# nrf54lv10a_application register map
Vendor: Nordic Semiconductor; Series: nrf54l; File version: 1
CPU: CM33 r0p4, little endian, MPU, FPU, 3 interrupt priority bits, 270 interrupts, 4 SAU regions
Registers are 32-bit, read-write, reset 0x0 unless marked. A register's access mark holds for its fields unless they carry their own. Offsets are from the block's base; [hi:lo] are bit positions; lines under a group give offsets from that group; {n}, {i} and the like mark numbered series; 'fields as' and 'values as' point back to an identical list.

## GLOBAL_RRAMC_S — RRAM controller GLITCH detector
Base 0x5004E000; alternate view of GLOBAL_GLITCHDET_S
0x00 TASKS_WAKEUP wo — Wakeup the RRAM from low power mode
  [0] TASKS_WAKEUP
    1=Trigger task
0x04 TASKS_CLRWRITEBUF wo — Clear internal write-buffer
  [0] TASKS_CLRWRITEBUF
    1=Trigger task
0x08 TASKS_COMMITWRITEBUF wo — Commits the data stored in internal write-buffer to RRAM
  [0] TASKS_COMMITWRITEBUF
    1=Trigger task
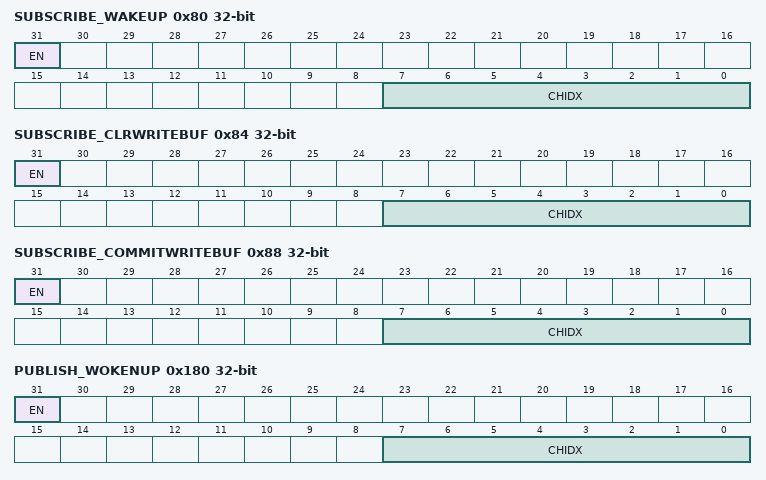
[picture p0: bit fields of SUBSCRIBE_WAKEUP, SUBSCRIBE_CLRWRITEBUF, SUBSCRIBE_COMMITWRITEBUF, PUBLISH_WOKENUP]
0x80 SUBSCRIBE_WAKEUP — Subscribe configuration for task WAKEUP
  [31] EN
    0=Disabled (Disable subscription); 1=Enabled (Enable subscription)
  [7:0] CHIDX — DPPI channel that task WAKEUP will subscribe to
0x84 SUBSCRIBE_CLRWRITEBUF — Subscribe configuration for task CLRWRITEBUF
  [31] EN
    values as SUBSCRIBE_WAKEUP.EN
  [7:0] CHIDX — DPPI channel that task CLRWRITEBUF will subscribe to
0x88 SUBSCRIBE_COMMITWRITEBUF — Subscribe configuration for task COMMITWRITEBUF
  [31] EN
    values as SUBSCRIBE_WAKEUP.EN
  [7:0] CHIDX — DPPI channel that task COMMITWRITEBUF will subscribe to
0x100 EVENTS_WOKENUP — RRAMC is woken up from low power mode
  [0] EVENTS_WOKENUP
    0=NotGenerated (Event not generated); 1=Generated (Event generated)
0x104 EVENTS_READY — RRAMC is ready
  [0] EVENTS_READY
    values as EVENTS_WOKENUP.EVENTS_WOKENUP
0x108 EVENTS_READYNEXT — Ready to accept a new write operation
  [0] EVENTS_READYNEXT
    values as EVENTS_WOKENUP.EVENTS_WOKENUP
0x10C EVENTS_ACCESSERROR — RRAM access error
  [0] EVENTS_ACCESSERROR
    values as EVENTS_WOKENUP.EVENTS_WOKENUP
0x180 PUBLISH_WOKENUP — Publish configuration for event WOKENUP
  [31] EN
    0=Disabled (Disable publishing); 1=Enabled (Enable publishing)
  [7:0] CHIDX — DPPI channel that event WOKENUP will publish to
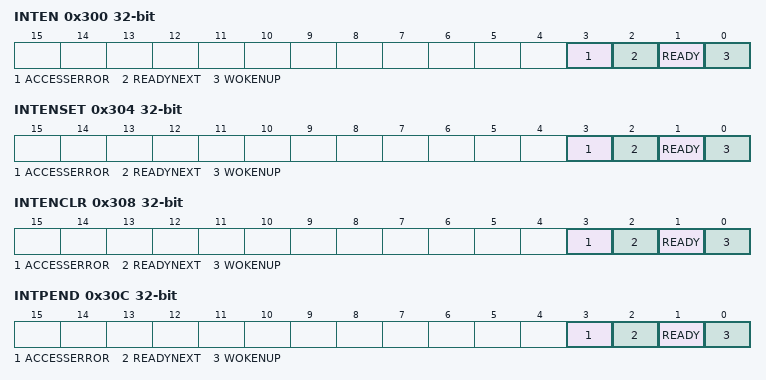
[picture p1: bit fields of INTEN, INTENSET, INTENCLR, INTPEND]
0x300 INTEN — Enable or disable interrupt
  [all] fields
    0=Disabled; 1=Enabled
  [3] ACCESSERROR — Enable or disable interrupt for event ACCESSERROR
  [2] READYNEXT — Enable or disable interrupt for event READYNEXT
  [1] READY — Enable or disable interrupt for event READY
  [0] WOKENUP — Enable or disable interrupt for event WOKENUP
0x304 INTENSET — Enable interrupt
  [all] fields
    on read: 0=Disabled (Read: Disabled); 1=Enabled (Read: Enabled) | on write: 1=Set (Enable)
  [3] ACCESSERROR write-1-sets — Write '1' to enable interrupt for event ACCESSERROR
  [2] READYNEXT write-1-sets — Write '1' to enable interrupt for event READYNEXT
  [1] READY write-1-sets — Write '1' to enable interrupt for event READY
  [0] WOKENUP write-1-sets — Write '1' to enable interrupt for event WOKENUP
0x308 INTENCLR — Disable interrupt
  [all] fields
    on read: 0=Disabled (Read: Disabled); 1=Enabled (Read: Enabled) | on write: 1=Clear (Disable)
  [3] ACCESSERROR write-1-clears — Write '1' to disable interrupt for event ACCESSERROR
  [2] READYNEXT write-1-clears — Write '1' to disable interrupt for event READYNEXT
  [1] READY write-1-clears — Write '1' to disable interrupt for event READY
  [0] WOKENUP write-1-clears — Write '1' to disable interrupt for event WOKENUP
0x30C INTPEND ro — Pending interrupts
  [all] fields
    on read: 0=NotPending (Read: Not pending); 1=Pending (Read: Pending)
  [3] ACCESSERROR — Read pending status of interrupt for event ACCESSERROR
  [2] READYNEXT — Read pending status of interrupt for event READYNEXT
  [1] READY — Read pending status of interrupt for event READY
  [0] WOKENUP — Read pending status of interrupt for event WOKENUP
0x400 READY ro — RRAMC ready status
  [0] READY — RRAMC is ready or busy
    0=Busy (RRAMC is busy); 1=Ready (The current RRAMC operation is completed and RRAMC is ready)
0x404 READYNEXT ro — Ready next flag
  [0] READYNEXT — RRAMC can accept a new write operation
    0=Busy (RRAMC cannot accept any write operation now); 1=Ready (RRAMC is ready to accept a new write operation)
0x408 ACCESSERRORADDR ro reset 0xFFFFFF — Address of the first access error
  [31:0] ADDRESS — Access error address
0x410 BUFSTATUS group — Unspecified
  0x08 WRITEBUFEMPTY ro — Internal write-buffer is empty
    [0] EMPTY
      0=NotEmpty (The internal write-buffer has data that needs committing); 1=Empty (The internal write-buffer is empty and has no content that needs to be committed)
0x420 ECC group — Unspecified
  0x00 ERRORADDR ro reset 0xFFFFFF — Address of the first ECC error that could not be corrected
    [31:0] ADDRESS — ECC error address
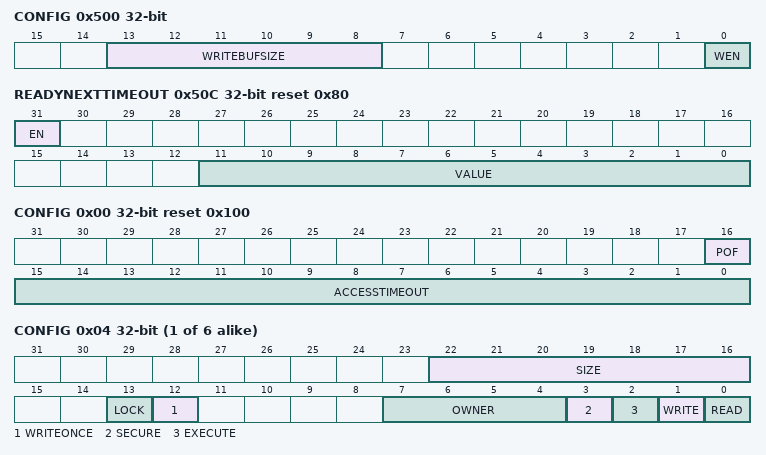
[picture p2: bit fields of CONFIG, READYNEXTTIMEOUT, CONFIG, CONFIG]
0x500 CONFIG — Configuration register
  [13:8] WRITEBUFSIZE — Write-buffer size in number of data units
    0=Unbuffered (Disable buffering)
  [0] WEN — Write enable
    0=Disabled (Write is disabled); 1=Enabled (Write is enabled)
0x50C READYNEXTTIMEOUT reset 0x80 — Configuration for ready next timeout counter, in units of AXI clock frequency
  [31] EN — Enable ready next timeout
    0=Disable ready next timeout; 1=Enable ready next timeout
  [11:0] VALUE — Preload value for waiting for a next write
0x510 POWER group — Unspecified
  0x00 CONFIG reset 0x100 — Power configuration
    [16] POF — Power on failure warning handling configuration
      0=Wait until the current RRAM write finishes; 1=Abort the current RRAM write
    [15:0] ACCESSTIMEOUT — Access timeout, in 31.25 ns units, used for going into standby power mode or remain active on wake up
  0x04 STANDBYCONFIG — Standby mode configuration
    [1:0] MODE — RRAM standby mode
      0=Normal (The RRAM automatically goes into idle mode while the RRAM is not being accessed); 1=NAP (The RRAM goes into NAP mode when the access timeout counter is expired); 2=PowerDown (The RRAM goes into power down mode when the access timeout counter is expired); 3=Standby (The RRAM remains active while the RRAM is not being accessed.)
  0x08 LOWPOWERCONFIG — Low power mode configuration
    [1:0] MODE — RRAM low power mode
      0=PowerDown (The RRAM goes into power down mode); 1=Standby (The RRAM automatically goes into standby mode while the RRAM is not being accessed); 2=NAP (The RRAM goes into NAP mode); 3=PowerOff (The RRAM is powered Off)
0x540 ERASE group — Unspecified
  0x00 ERASEALL — Erase RRAM, including UICR All information in SICR, including keys, are also erased
    [0] ERASE — Erase RRAM
      0=NoOperation; 1=Erase (Start erase of chip)
{0x550+8i} REGION[{i}] (i=0..5) group — RRAMC can apply access privileges to regions of the RRAM. Some regions are dedicated for system use and are not available for configuration - refer to the instantiation table for details.
  0x00 ADDRESS — Description cluster: Region address
    [31:0] STARTADDR — Start address of the region [n]
  0x04 CONFIG — Description cluster: Region configuration
    [22:16] SIZE — Size in KBytes of region [n]
    [13] LOCK write-1-sets — Enable lock
      0=Disabled (Lock disabled for region [n]); 1=Enabled (Lock enabled for region [n])
    [12] WRITEONCE
      0=Disabled (Write-once disabled); 1=Enabled (Write-once enabled)
    [7:4] OWNER — Owner ID
      0=NotEnforced (Owner ID protection is not enforced)
    [3] SECURE — Secure access
      0=NonSecure (Both Secure and non-Secure access to override region [n] is allowed); 1=Secure (Only secure access to override region [n] is allowed)
    [2] EXECUTE — Execute access
      0=NotAllowed (Execute access to override region [n] is not allowed); 1=Allowed (Execute access to override region [n] is allowed)
    [1] WRITE — Write access
      0=NotAllowed (Write access to override region [n] is not allowed); 1=Allowed (Write access to override region [n] is allowed)
    [0] READ — Read access
      0=NotAllowed (Read access to override region [n] is not allowed); 1=Allowed (Read access to override region [n] is allowed)

## Notices in the file
Copyright (c) 2010 - 2026, Nordic Semiconductor ASA All rights reserved.
SPDX-License-Identifier: BSD-3-Clause
Redistribution and use in source and binary forms, with or without
modification, are permitted provided that the following conditions are met:
1. Redistributions of source code must retain the above copyright notice, this
list of conditions and the following disclaimer.
2. Redistributions in binary form must reproduce the above copyright
notice, this list of conditions and the following disclaimer in the
documentation and/or other materials provided with the distribution.
3. Neither the name of Nordic Semiconductor ASA nor the names of its
contributors may be used to endorse or promote products derived from this
software without specific prior written permission.
THIS SOFTWARE IS PROVIDED BY THE COPYRIGHT HOLDERS AND CONTRIBUTORS "AS IS"
AND ANY EXPRESS OR IMPLIED WARRANTIES, INCLUDING, BUT NOT LIMITED TO, THE
IMPLIED WARRANTIES OF MERCHANTABILITY, AND FITNESS FOR A PARTICULAR PURPOSE
ARE DISCLAIMED. IN NO EVENT SHALL NORDIC SEMICONDUCTOR ASA OR CONTRIBUTORS BE
LIABLE FOR ANY DIRECT, INDIRECT, INCIDENTAL, SPECIAL, EXEMPLARY, OR
CONSEQUENTIAL DAMAGES (INCLUDING, BUT NOT LIMITED TO, PROCUREMENT OF
SUBSTITUTE GOODS OR SERVICES; LOSS OF USE, DATA, OR PROFITS; OR BUSINESS
INTERRUPTION) HOWEVER CAUSED AND ON ANY THEORY OF LIABILITY, WHETHER IN
CONTRACT, STRICT LIABILITY, OR TORT (INCLUDING NEGLIGENCE OR OTHERWISE)
ARISING IN ANY WAY OUT OF THE USE OF THIS SOFTWARE, EVEN IF ADVISED OF THE
POSSIBILITY OF SUCH DAMAGE.
